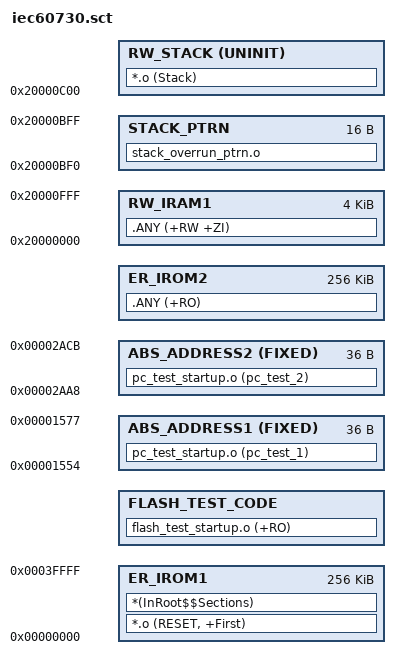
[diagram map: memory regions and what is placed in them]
; *************************************************************
; *** Scatter-Loading Description File generated by uVision ***
; *************************************************************

LR_IROM1 0x00000000         {    ; load region
  ER_IROM1 0x00000000 0x00040000  {  ; load address = execution address
   *.o (RESET, +First)
   *(InRoot$$Sections)
;	*.o (CHECKSUM, +Last)
  }
  
  FLASH_TEST_CODE +0
  {
    flash_test_startup.o (+RO)
  }
  
;  ABS_ADDRESS1 0x1F400 FIXED 4 {
  ABS_ADDRESS1 0x1554 FIXED 36 {			
    pc_test_startup.o (pc_test_1)
  }
  
;  ABS_ADDRESS2 0x410 FIXED 8 {
  ABS_ADDRESS2 0x2AA8 FIXED 36 {
    pc_test_startup.o (pc_test_2)
  }
  
  ER_IROM2 +0 0x00040000  {  	; load address = execution address
   .ANY (+RO)
  } 

;  ABS_ADDRESS3 0x8000-0x100 FIXED 36 {
;	*.o (CHECKSUM +Last)   
;  }
  
  RW_IRAM1 0x20000000 0x00001000  {				; RW data
   .ANY (+RW +ZI)
  }
  
  RW_STACK 0x20001000-0x0400 UNINIT ALIGN 16	; RW data - Stack
  {
    *.o (Stack)				; stack size is 0x0400
  }
  
  STACK_PTRN 0x20001000-0x0400-0x0010 0x0010 	; RO data
  {  
    stack_overrun_ptrn.o
  }

;  CLASS_B 0x20001000-0x0500 	; class B variables
;  {  
;   ram_marchc_test_runtime.o (CLASS_B_RAM)
;  }

}

